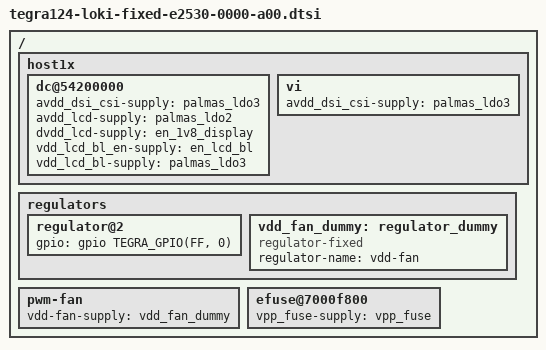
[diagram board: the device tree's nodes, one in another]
#include "tegra124-loki-fixed-e2545-0000-common.dtsi"

/ {
	host1x {
		/* tegradc.0 */
		dc@54200000 {
			avdd_dsi_csi-supply = <&palmas_ldo3>;
			avdd_lcd-supply = <&palmas_ldo2>;
			dvdd_lcd-supply = <&en_1v8_display>;
			vdd_lcd_bl_en-supply = <&en_lcd_bl>;
			vdd_lcd_bl-supply = <&palmas_ldo3>;
		};
		vi {
			avdd_dsi_csi-supply = <&palmas_ldo3>;
		};
	};

	regulators {
		regulator@2 {
			gpio = <&gpio TEGRA_GPIO(FF, 0) 0>;
		};
		vdd_fan_dummy: regulator_dummy {
			compatible = "regulator-fixed";
			regulator-name = "vdd-fan";
		};
	};

	pwm-fan {
		vdd-fan-supply = <&vdd_fan_dummy>;
	};

	/* Populate fuse supply */
	efuse@7000f800 {
		vpp_fuse-supply = <&vpp_fuse>;
	};
};
